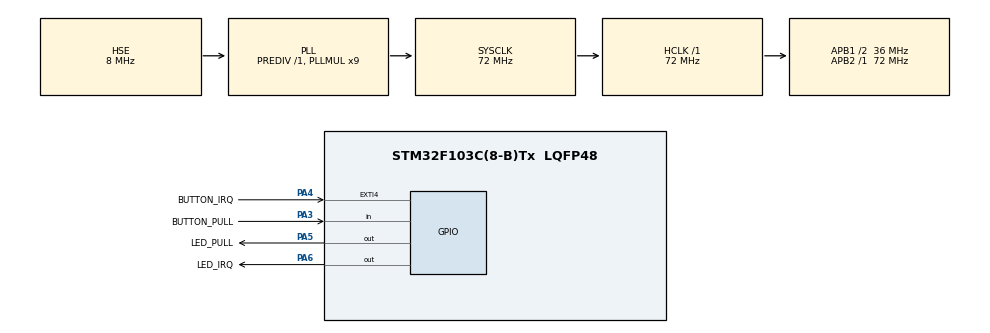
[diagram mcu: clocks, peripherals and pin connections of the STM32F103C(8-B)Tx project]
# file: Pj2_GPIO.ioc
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Mcu.Family=STM32F1
Mcu.Name=STM32F103C(8-B)Tx
Mcu.Package=LQFP48
NVIC.EXTI4_IRQn=true\:0\:0\:false\:false\:true\:true\:true\:true
NVIC.PriorityGroup=NVIC_PRIORITYGROUP_4
PA13.Mode=Serial_Wire
PA13.Signal=SYS_JTMS-SWDIO
PA14.Mode=Serial_Wire
PA14.Signal=SYS_JTCK-SWCLK
PA3.GPIO_Label=BUTTON_PULL
PA3.Signal=GPIO_Input
PA4.GPIO_Label=BUTTON_IRQ
PA4.GPIO_ModeDefaultEXTI=GPIO_MODE_IT_FALLING
PA4.Signal=GPXTI4
PA5.GPIO_Label=LED_PULL
PA5.Signal=GPIO_Output
PA6.GPIO_Label=LED_IRQ
PA6.Signal=GPIO_Output
PD0-OSC_IN.Mode=HSE-External-Oscillator
PD0-OSC_IN.Signal=RCC_OSC_IN
PD1-OSC_OUT.Mode=HSE-External-Oscillator
PD1-OSC_OUT.Signal=RCC_OSC_OUT
ProjectManager.HeapSize=0x200
ProjectManager.StackSize=0x400
ProjectManager.TargetToolchain=STM32CubeIDE
RCC.AHBFreq_Value=72000000
RCC.APB1CLKDivider=RCC_HCLK_DIV2
RCC.APB1Freq_Value=36000000
RCC.APB1TimFreq_Value=72000000
RCC.APB2Freq_Value=72000000
RCC.APB2TimFreq_Value=72000000
RCC.HCLKFreq_Value=72000000
RCC.PLLMUL=RCC_PLL_MUL9
RCC.PLLSourceVirtual=RCC_PLLSOURCE_HSE
RCC.SYSCLKFreq_VALUE=72000000
RCC.SYSCLKSource=RCC_SYSCLKSOURCE_PLLCLK
RCC.USBFreq_Value=72000000
board=custom

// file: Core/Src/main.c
#include "main.h"

void SystemClock_Config(void);
static void MX_GPIO_Init(void);

int main(void)
{
  HAL_Init();
  SystemClock_Config();
  MX_GPIO_Init();

  while (1)
  {
	  GPIO_PinState state = HAL_GPIO_ReadPin(BUTTON_PULL_GPIO_Port, BUTTON_PULL_Pin);
	  HAL_GPIO_WritePin(LED_PULL_GPIO_Port, LED_PULL_Pin, state);
	  HAL_Delay(4000);

  }

}

void SystemClock_Config(void)
{
  RCC_OscInitTypeDef RCC_OscInitStruct = {0};
  RCC_ClkInitTypeDef RCC_ClkInitStruct = {0};
  RCC_OscInitStruct.OscillatorType = RCC_OSCILLATORTYPE_HSE;
  RCC_OscInitStruct.HSEState = RCC_HSE_ON;
  RCC_OscInitStruct.HSEPredivValue = RCC_HSE_PREDIV_DIV1;
  RCC_OscInitStruct.HSIState = RCC_HSI_ON;
  RCC_OscInitStruct.PLL.PLLState = RCC_PLL_ON;
  RCC_OscInitStruct.PLL.PLLSource = RCC_PLLSOURCE_HSE;
  RCC_OscInitStruct.PLL.PLLMUL = RCC_PLL_MUL9;
  if (HAL_RCC_OscConfig(&RCC_OscInitStruct) != HAL_OK)
  {
    Error_Handler();
  }

  RCC_ClkInitStruct.ClockType = RCC_CLOCKTYPE_HCLK|RCC_CLOCKTYPE_SYSCLK
                              |RCC_CLOCKTYPE_PCLK1|RCC_CLOCKTYPE_PCLK2;
  RCC_ClkInitStruct.SYSCLKSource = RCC_SYSCLKSOURCE_PLLCLK;
  RCC_ClkInitStruct.AHBCLKDivider = RCC_SYSCLK_DIV1;
  RCC_ClkInitStruct.APB1CLKDivider = RCC_HCLK_DIV2;
  RCC_ClkInitStruct.APB2CLKDivider = RCC_HCLK_DIV1;

  if (HAL_RCC_ClockConfig(&RCC_ClkInitStruct, FLASH_LATENCY_2) != HAL_OK)
  {
    Error_Handler();
  }
}

static void MX_GPIO_Init(void)
{
  GPIO_InitTypeDef GPIO_InitStruct = {0};
  __HAL_RCC_GPIOD_CLK_ENABLE();
  __HAL_RCC_GPIOA_CLK_ENABLE();

  /*Configure GPIO pin Output Level */
  HAL_GPIO_WritePin(GPIOA, LED_PULL_Pin|LED_IRQ_Pin, GPIO_PIN_RESET);

  /*Configure GPIO pin : BUTTON_PULL_Pin */
  GPIO_InitStruct.Pin = BUTTON_PULL_Pin;
  GPIO_InitStruct.Mode = GPIO_MODE_INPUT;
  GPIO_InitStruct.Pull = GPIO_NOPULL;
  HAL_GPIO_Init(BUTTON_PULL_GPIO_Port, &GPIO_InitStruct);

  /*Configure GPIO pin : BUTTON_IRQ_Pin */
  GPIO_InitStruct.Pin = BUTTON_IRQ_Pin;
  GPIO_InitStruct.Mode = GPIO_MODE_IT_FALLING;
  GPIO_InitStruct.Pull = GPIO_NOPULL;
  HAL_GPIO_Init(BUTTON_IRQ_GPIO_Port, &GPIO_InitStruct);

  /*Configure GPIO pins : LED_PULL_Pin LED_IRQ_Pin */
  GPIO_InitStruct.Pin = LED_PULL_Pin|LED_IRQ_Pin;
  GPIO_InitStruct.Mode = GPIO_MODE_OUTPUT_PP;
  GPIO_InitStruct.Pull = GPIO_NOPULL;
  GPIO_InitStruct.Speed = GPIO_SPEED_FREQ_LOW;
  HAL_GPIO_Init(GPIOA, &GPIO_InitStruct);

  /* EXTI interrupt init*/
  HAL_NVIC_SetPriority(EXTI4_IRQn, 0, 0);
  HAL_NVIC_EnableIRQ(EXTI4_IRQn);

}

/* USER CODE BEGIN 4 */
void HAL_GPIO_EXTI_Callback(uint16_t GPIO_Pin){
	if(BUTTON_IRQ_Pin == GPIO_Pin) {
		HAL_GPIO_TogglePin(LED_IRQ_GPIO_Port, LED_IRQ_Pin);
	};

}
/* USER CODE END 4 */

void Error_Handler(void)
{
  __disable_irq();
  while (1)
  {
  }
}
